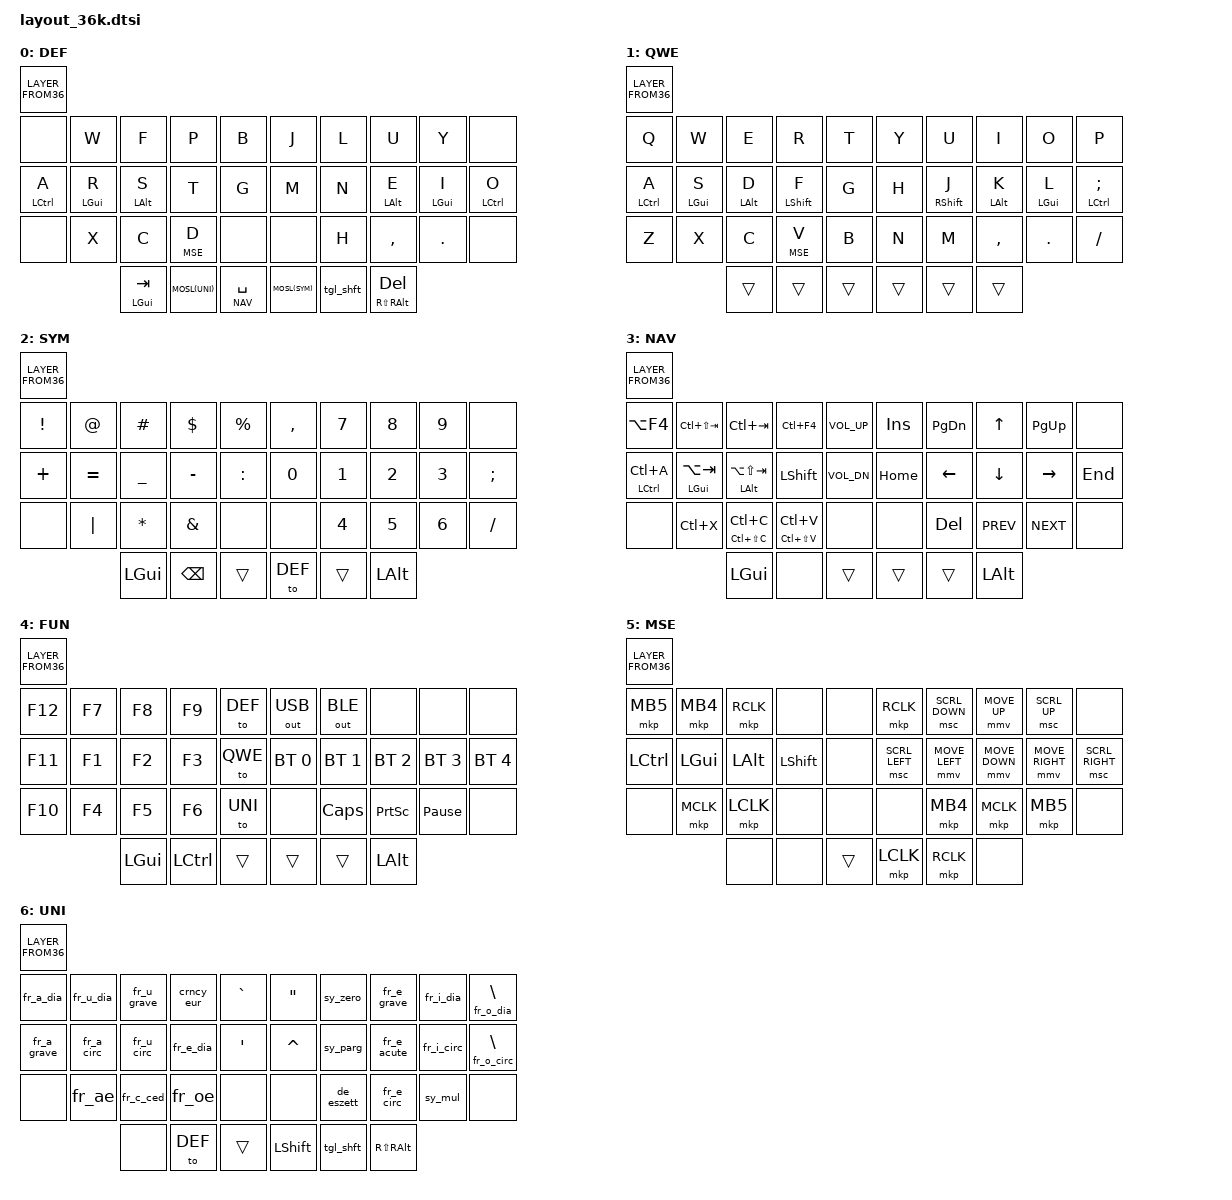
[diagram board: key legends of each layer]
/********** includes **********/ 
#include <behaviors.dtsi>
#include <behaviors/num_word.dtsi> // Requires auto-layer module.
#include <dt-bindings/zmk/keys.h>
#include <dt-bindings/zmk/bt.h>
#include <dt-bindings/zmk/outputs.h>

/********** layers **********/ 
#define DEF 0
#define QWE 1
#define SYM 2
#define NAV 3
#define FUN 4
#define MSE 5
#define UNI 6

/********** settings **********/ 
#define HOST_OS 1
#define XXX &none
#define ___ &trans
#define tcopy &tpht LC(LS(C)) LC(C)
#define tpaste &tpht LC(LS(V)) LC(V)

/********** other includes **********/ 
#include "combos.dtsi"
#include "mouse.dtsi"
#include "unicode.dtsi"

/********** macros **********/ 
// macro to apply momemtary layer on hold, and sticky layer on tap
// usually, in the destination layer, set the same key to &to <initial layer>
#define MOSL(layer) &mo_sl layer layer

/********** Global defaults **********/ 
&mt {
    flavor = "hold-preferred";
    tapping-term-ms = <250>;
};

&lt {
    flavor = "balanced";
    tapping-term-ms = <250>;
};

&caps_word {
    continue-list = <UNDERSCORE MINUS BSPC DEL N1 N2 N3 N4 N5 N6 N7 N8 N9 N0>;
    mods = <(MOD_LSFT)>;
};

&sl {
    release-after-ms = <2000>;
};


/********** layouts **********/ 
/ {
    behaviors {
        // home-row mods
        aml: alpha_mods_l {
            compatible = "zmk,behavior-hold-tap";
            #binding-cells = <2>;
            tapping-term-ms = <250>;
            quick-tap-ms = <150>;
            flavor = "balanced";
            bindings = <&kp>, <&kp>;
            hold-trigger-key-positions = <KEYS_R THUMBS>;
            // hold-trigger-on-release;
            require-prior-idle-ms = <150>;
        };
        asl: alpha_shift_l {
            compatible = "zmk,behavior-hold-tap";
            #binding-cells = <2>;
            tapping-term-ms = <200>;
            quick-tap-ms = <100>;
            flavor = "balanced";
            bindings = <&kp>, <&kp>;
            hold-trigger-key-positions = <KEYS_R THUMBS>;
            // hold-trigger-on-release;
        };
        amr: alpha_mods_r {
            compatible = "zmk,behavior-hold-tap";
            #binding-cells = <2>;
            tapping-term-ms = <250>;
            quick-tap-ms = <150>;
            flavor = "balanced";
            bindings = <&kp>, <&kp>;
            hold-trigger-key-positions = <KEYS_L THUMBS>;
            // hold-trigger-on-release;
            require-prior-idle-ms = <150>;
        };
        asr: alpha_shift_r {
            compatible = "zmk,behavior-hold-tap";
            #binding-cells = <2>;
            tapping-term-ms = <200>;
            quick-tap-ms = <100>;
            flavor = "balanced";
            bindings = <&kp>, <&kp>;
            hold-trigger-key-positions = <KEYS_L THUMBS>;
            // hold-trigger-on-release;
        };

        // Swapper for smart alt+tab
        swapper: swapper {
            compatible = "zmk,behavior-smart-toggle";
            #binding-cells = <0>;
            bindings = <&kp LALT>, <&kp TAB>;
            ignored-key-positions = <LM3 RM1 RM2 RM3 RT2>;
        };
        ht_sw: ht_sw {
            compatible = "zmk,behavior-hold-tap";
            #binding-cells = <2>;
            tapping-term-ms = <150>;
            flavor = "hold-preferred";
            bindings = <&kp>, <&swapper>;
        };

        rst_boot: rst_boot {
            compatible = "zmk,behavior-hold-tap";
            #binding-cells = <2>;
            tapping-term-ms = <500>;
            flavor = "tap-preferred";
            bindings = <&bootloader>, <&sys_reset>;
        };

        tpht: tpht {
            compatible = "zmk,behavior-hold-tap";
            #binding-cells = <2>;
            tapping-term-ms = <200>;
            flavor = "tap-preferred";
            bindings = <&kp>, <&kp>;
        };

        splt: space_layer_tap {
            compatible = "zmk,behavior-hold-tap";
            #binding-cells = <2>;
            tapping-term-ms = <200>;
            quick-tap-ms = <175>;
            require-prior-idle-ms = <150>;
            flavor = "balanced";
            bindings = <&kp>, <&kp>;
        };

        mo_sl: mo_sl_hold_tap {
            compatible = "zmk,behavior-hold-tap";
            #binding-cells = <2>;
            tapping-term-ms = <200>;
            flavor = "hold-preferred";
            bindings = <&mo>, <&sl>;
        };

        slqr: sticky_layer_quick_release {
            compatible = "zmk,behavior-sticky-key";
            #binding-cells = <1>;
            bindings = <&kp>;
            release-after-ms = <2000>;
            quick-release;
        };

        tgl_shft: togl_shft {
            compatible = "zmk,behavior-mod-morph";
            #binding-cells = <0>;
            bindings = <&slqr LSHFT>, <&kp K_CANCEL>;  // hack: F13 consumes the sticky shift, with hopefully no side effect
            mods = <(MOD_LSFT|MOD_RSFT)>;
        };

        arrw: single_arrow {
            compatible = "zmk,behavior-macro";
            #binding-cells = <0>;
            bindings = <&macro_tap &kp MINUS>, <&macro_tap &kp GT>;
        };

        dbarrw: double_arrow {
            compatible = "zmk,behavior-macro";
            #binding-cells = <0>;
            bindings = <&macro_tap &kp EQUAL>, <&macro_tap &kp GT>;
        };
    };

    cond_layers {
        compatible = "zmk,conditional-layers";

        // Define FUN as tri-state
        func_tristate {
            if-layers = <NAV SYM>;
            then-layer = <FUN>;
        };
    };

    keymap {
        compatible = "zmk,keymap";

        default_layer {
            display-name = "DEF";
            bindings = <LAYER_FROM36( \
// ╭─────────────┬─────────────┬─────────────┬─────────────┬─────────────╮   ╭─────────────┬─────────────┬─────────────┬─────────────┬─────────────╮
     &none,        &kp W,        &kp F,        &kp P,        &kp B,            &kp J,        &kp L,        &kp U,        &kp Y,        &none,        \
// ├─────────────┼─────────────┼─────────────┼─────────────┼─────────────┤   ├─────────────┼─────────────┼─────────────┼─────────────┼─────────────┤
     &aml LCTRL A, &aml LGUI R,  &aml LALT S,  &kp T,        &kp G,            &kp M,        &kp N,        &amr LALT E,  &amr LGUI I,  &amr LCTRL O, \
// ├─────────────┼─────────────┼─────────────┼─────────────┼─────────────┤   ├─────────────┼─────────────┼─────────────┼─────────────┼─────────────┤
     &none,        &kp X,        &kp C,        &lt MSE D,    &none,            &none,        &kp H,        &kp COMMA,    &kp DOT,      &none,        \
// ╰─────────────┴─────────────┴─────────────┼─────────────┼─────────────┤   ├─────────────┼─────────────┼─────────────┴─────────────┴─────────────╯
                                &mt LGUI TAB,  MOSL(UNI),   &lt NAV SPACE,     MOSL(SYM),    &tgl_shft,   &mt RS(RALT) DEL
//                             ╰─────────────┴─────────────┴─────────────╯   ╰─────────────┴─────────────┴─────────────╯
            )>;
        };

        qwerty_layer {
            display-name = "QWE";
            bindings = <LAYER_FROM36( \
// ╭─────────────┬─────────────┬─────────────┬─────────────┬─────────────╮   ╭─────────────┬─────────────┬─────────────┬─────────────┬─────────────╮
     &kp Q,        &kp W,        &kp E,        &kp R,        &kp T,            &kp Y,        &kp U,        &kp I,        &kp O,        &kp P,        \
// ├─────────────┼─────────────┼─────────────┼─────────────┼─────────────┤   ├─────────────┼─────────────┼─────────────┼─────────────┼─────────────┤
     &aml LCTRL A, &aml LGUI S,  &aml LALT D,  &asl LSHFT F, &kp G,            &kp H,        &asr RSHFT J, &amr LALT K,  &amr LGUI L,  &amr LCTRL SEMI, \
// ├─────────────┼─────────────┼─────────────┼─────────────┼─────────────┤   ├─────────────┼─────────────┼─────────────┼─────────────┼─────────────┤
     &kp Z,        &kp X,        &kp C,        &lt MSE V,    &kp B,            &kp N,        &kp M,        &kp COMMA,    &kp DOT,      &kp SLASH,    \
// ╰─────────────┴─────────────┴─────────────┼─────────────┼─────────────┤   ├─────────────┼─────────────┼─────────────┴─────────────┴─────────────╯
                                  &trans,       &trans,      &trans,           &trans,       &trans,       &trans
//                             ╰─────────────┴─────────────┴─────────────╯   ╰─────────────┴─────────────┴─────────────╯
            )>;
        };

        symbols_layer {
            display-name = "SYM";
            bindings = <LAYER_FROM36( \
// ╭─────────────┬─────────────┬─────────────┬─────────────┬─────────────╮   ╭─────────────┬─────────────┬─────────────┬─────────────┬─────────────╮
     &kp EXCL,     &kp AT,       &kp HASH,     &kp DLLR,     &kp PRCNT,        &kp COMMA,    &kp N7,       &kp N8,       &kp N9,       &none,        \
// ├─────────────┼─────────────┼─────────────┼─────────────┼─────────────┤   ├─────────────┼─────────────┼─────────────┼─────────────┼─────────────┤
     &kp PLUS,     &kp EQUAL,    &kp UNDER,    &kp MINUS,    &kp COLON,        &kp N0,       &kp N1,       &kp N2,       &kp N3,       &kp SEMI,     \
// ├─────────────┼─────────────┼─────────────┼─────────────┼─────────────┤   ├─────────────┼─────────────┼─────────────┼─────────────┼─────────────┤
     &none,        &kp PIPE,     &kp STAR,     &kp AMPS,     &none,            &none,        &kp N4,       &kp N5,       &kp N6,       &kp SLASH,    \
// ╰─────────────┴─────────────┴─────────────┼─────────────┼─────────────┤   ├─────────────┼─────────────┼─────────────┴─────────────┴─────────────╯
                                 &kp LGUI,     &kp BSPC,     &trans,           &to DEF,       &trans,        &kp LALT
//                             ╰─────────────┴─────────────┴─────────────╯   ╰─────────────┴─────────────┴─────────────╯
            )>;
        };

        nav_layer {
            display-name = "NAV";
            bindings = <LAYER_FROM36( \
// ╭─────────────┬─────────────┬─────────────┬─────────────┬─────────────╮   ╭─────────────┬─────────────┬─────────────┬─────────────┬─────────────╮
     &kp LA(F4), &kp LC(LS(TAB)), &kp LC(TAB), &kp LC(F4),   &kp C_VOL_UP,      &kp INS,      &kp PG_DN,    &kp UP,       &kp PG_UP,    &none,        \
// ├─────────────┼─────────────┼─────────────┼─────────────┼─────────────┤   ├─────────────┼─────────────┼─────────────┼─────────────┼─────────────┤
&mt LCTRL LC(A), &mt LGUI LA(TAB), &mt LALT LA(LS(TAB)), &kp LSHFT, &kp C_VOL_DN, &kp HOME,  &kp LEFT,     &kp DOWN,     &kp RIGHT,    &kp END,      \
// ├─────────────┼─────────────┼─────────────┼─────────────┼─────────────┤   ├─────────────┼─────────────┼─────────────┼─────────────┼─────────────┤
     &none,        &kp LC(X), &tpht LC(LS(C)) LC(C), &tpht LC(LS(V)) LC(V), &none, &none,     &kp DEL,      &kp C_PREV,   &kp C_NEXT,   &none,        \
// ╰─────────────┴─────────────┴─────────────┼─────────────┼─────────────┤   ├─────────────┼─────────────┼─────────────┴─────────────┴─────────────╯
                                 &kp LGUI,     &none,        &trans,            &trans,       &trans,       &kp LALT
//                             ╰─────────────┴─────────────┴─────────────╯   ╰─────────────┴─────────────┴─────────────╯
            )>;
        };

        fun_layer {
            display-name = "FUN";
            bindings = <LAYER_FROM36( \
// ╭─────────────┬─────────────┬─────────────┬─────────────┬─────────────╮   ╭─────────────┬─────────────┬─────────────┬─────────────┬─────────────╮
     &kp F12,      &kp F7,       &kp F8,       &kp F9,       &to DEF,          &out OUT_USB, &out OUT_BLE, &none,        &none,        &none,        \
// ├─────────────┼─────────────┼─────────────┼─────────────┼─────────────┤   ├─────────────┼─────────────┼─────────────┼─────────────┼─────────────┤
     &kp F11,      &kp F1,       &kp F2,       &kp F3,       &to QWE,          &bt BT_SEL 0, &bt BT_SEL 1, &bt BT_SEL 2, &bt BT_SEL 3, &bt BT_SEL 4, \
// ├─────────────┼─────────────┼─────────────┼─────────────┼─────────────┤   ├─────────────┼─────────────┼─────────────┼─────────────┼─────────────┤
     &kp F10,      &kp F4,       &kp F5,       &kp F6,       &to UNI,           &none,        &kp CAPS,     &kp PSCRN, &kp PAUSE_BREAK, &none,       \
// ╰─────────────┴─────────────┴─────────────┼─────────────┼─────────────┤   ├─────────────┼─────────────┼─────────────┴─────────────┴─────────────╯
                                 &kp LGUI,     &kp LCTRL,     &trans,           &trans,       &trans,       &kp LALT
//                             ╰─────────────┴─────────────┴─────────────╯   ╰─────────────┴─────────────┴─────────────╯
            )>;
        };

        mouse_layer {
            display-name = "MSE";
            bindings = <LAYER_FROM36( \
// ╭─────────────┬─────────────┬─────────────┬─────────────┬─────────────╮   ╭─────────────┬─────────────┬─────────────┬─────────────┬─────────────╮
     &mkp MB5,     &mkp MB4,     &mkp RCLK,    &none,        &none,            &mkp RCLK,  &msc SCRL_DOWN, &mmv MOVE_UP, &msc SCRL_UP, &none,                \
// ├─────────────┼─────────────┼─────────────┼─────────────┼─────────────┤   ├─────────────┼─────────────┼─────────────┼─────────────┼─────────────┤
     &kp LCTRL,    &kp LGUI,     &kp LALT,     &kp LSHFT,    &none,        &msc SCRL_LEFT, &mmv MOVE_LEFT, &mmv MOVE_DOWN, &mmv MOVE_RIGHT, &msc SCRL_RIGHT, \
// ├─────────────┼─────────────┼─────────────┼─────────────┼─────────────┤   ├─────────────┼─────────────┼─────────────┼─────────────┼─────────────┤
     &none,        &mkp MCLK,    &mkp LCLK,    &none,        &none,            &none,        &mkp MB4,     &mkp MCLK,    &mkp MB5,     &none,                \
// ╰─────────────┴─────────────┴─────────────┼─────────────┼─────────────┤   ├─────────────┼─────────────┼─────────────┴─────────────┴─────────────╯
                                 &none,        &none,        &trans,           &mkp LCLK,    &mkp RCLK,    &none                                             \
//                             ╰─────────────┴─────────────┴─────────────╯   ╰─────────────┴─────────────┴─────────────╯
            )>;
        };

        unicode_layer {
            display-name = "UNI";
            bindings = <LAYER_FROM36( \
// ╭─────────────┬─────────────┬─────────────┬─────────────┬─────────────╮   ╭─────────────┬─────────────┬─────────────┬─────────────┬─────────────╮
     &fr_a_dia,     &fr_u_dia,   &fr_u_grave,  &crncy_eur,   &kp GRAVE,        &kp DQT,      &sy_zero,     &fr_e_grave,  &fr_i_dia,    &fr_o_dia,    \
// ├─────────────┼─────────────┼─────────────┼─────────────┼─────────────┤   ├─────────────┼─────────────┼─────────────┼─────────────┼─────────────┤
     &fr_a_grave,   &fr_a_circ,  &fr_u_circ,   &fr_e_dia,    &kp SQT,          &kp CARET,    &sy_parg,     &fr_e_acute,  &fr_i_circ,   &fr_o_circ,   \
// ├─────────────┼─────────────┼─────────────┼─────────────┼─────────────┤   ├─────────────┼─────────────┼─────────────┼─────────────┼─────────────┤
     &none,        &fr_ae,       &fr_c_ced,    &fr_oe,       &none,            &none,        &de_eszett,   &fr_e_circ,    &sy_mul,      &none,        \
// ╰─────────────┴─────────────┴─────────────┼─────────────┼─────────────┤   ├─────────────┼─────────────┼─────────────┴─────────────┴─────────────╯
                                 &none,        &to DEF,      &trans,           &kp LSHFT,    &tgl_shft,     &kp RS(RALT)
//                             ╰─────────────┴─────────────┴─────────────╯   ╰─────────────┴─────────────┴─────────────╯
            )>;
        };

    };

};

/* vim: set ft=c tw=146: */
